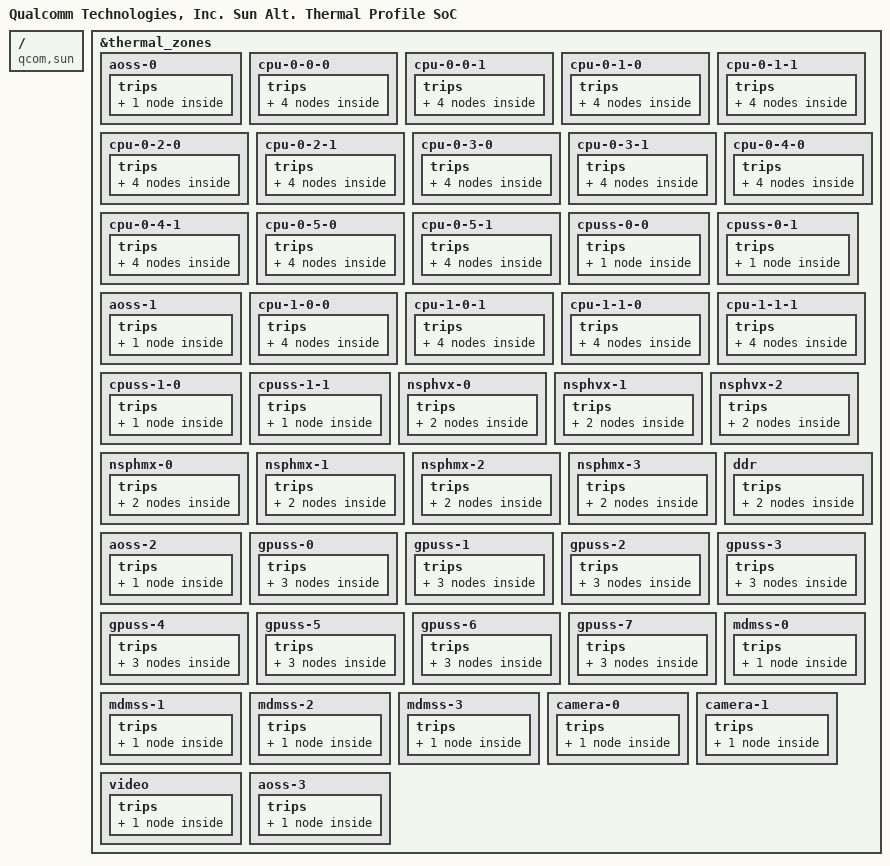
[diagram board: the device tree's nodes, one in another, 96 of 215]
// SPDX-License-Identifier: BSD-3-Clause
/*
 * Copyright (c) 2024 Qualcomm Innovation Center, Inc. All rights reserved.
 */

/ {
	model = "Qualcomm Technologies, Inc. Sun Alt. Thermal Profile SoC";
	compatible = "qcom,sun";
	qcom,msm-id = <0x100026a 0x10000>;
};

&thermal_zones {
	aoss-0 {
		trips {
			reset-mon-cfg {
				temperature = <125000>;
			};
		};
	};

	cpu-0-0-0 {
		trips {
			thermal-hal-config {
				temperature = <105000>;
			};

			cpu0-emerg0-cfg {
				temperature = <95000>;
			};

			cpu0-emerg0-1-cfg {
				temperature = <120000>;
			};

			reset-mon-cfg {
				temperature = <125000>;
			};
		};
	};

	cpu-0-0-1 {
		trips {
			thermal-hal-config {
				temperature = <105000>;
			};

			cpu0-emerg1-cfg {
				temperature = <118000>;
			};

			cpu0-emerg1-1-cfg {
				temperature = <120000>;
			};

			reset-mon-cfg {
				temperature = <125000>;
			};
		};
	};

	cpu-0-1-0 {
		trips {
			thermal-hal-config {
				temperature = <105000>;
			};

			cpu1-emerg0-cfg {
				temperature = <118000>;
			};

			cpu1-emerg0-1-cfg {
				temperature = <120000>;
			};

			reset-mon-cfg {
				temperature = <125000>;
			};
		};
	};

	cpu-0-1-1 {
		trips {
			thermal-hal-config {
				temperature = <105000>;
			};

			cpu1-emerg1-cfg {
				temperature = <118000>;
			};

			cpu1-emerg1-1-cfg {
				temperature = <120000>;
			};

			reset-mon-cfg {
				temperature = <125000>;
			};
		};
	};

	cpu-0-2-0 {
		trips {
			thermal-hal-config {
				temperature = <105000>;
			};

			cpu2-emerg0-cfg {
				temperature = <95000>;
			};

			cpu2-emerg0-1-cfg {
				temperature = <120000>;
			};

			reset-mon-cfg {
				temperature = <125000>;
			};
		};
	};

	cpu-0-2-1 {
		trips {
			thermal-hal-config {
				temperature = <105000>;
			};

			cpu2-emerg1-cfg {
				temperature = <95000>;
			};

			cpu2-emerg1-1-cfg {
				temperature = <120000>;
			};

			reset-mon-cfg {
				temperature = <125000>;
			};
		};
	};

	cpu-0-3-0 {
		trips {
			thermal-hal-config {
				temperature = <105000>;
			};

			cpu3-emerg0-cfg {
				temperature = <118000>;
			};

			cpu3-emerg0-1-cfg {
				temperature = <120000>;
			};

			reset-mon-cfg {
				temperature = <125000>;
			};
		};
	};

	cpu-0-3-1 {
		trips {
			thermal-hal-config {
				temperature = <105000>;
			};

			cpu3-emerg1-cfg {
				temperature = <118000>;
			};

			cpu3-emerg1-1-cfg {
				temperature = <120000>;
			};

			reset-mon-cfg {
				temperature = <125000>;
			};
		};
	};

	cpu-0-4-0 {
		trips {
			thermal-hal-config {
				temperature = <105000>;
			};

			cpu4-emerg0-cfg {
				temperature = <95000>;
			};

			cpu4-emerg0-1-cfg {
				temperature = <120000>;
			};

			reset-mon-cfg {
				temperature = <125000>;
			};
		};
	};

	cpu-0-4-1 {
		trips {
			thermal-hal-config {
				temperature = <105000>;
			};

			cpu4-emerg1-cfg {
				temperature = <95000>;
			};

			cpu4-emerg1-1-cfg {
				temperature = <120000>;
			};

			reset-mon-cfg {
				temperature = <125000>;
			};
		};
	};

	cpu-0-5-0 {
		trips {
			thermal-hal-config {
				temperature = <105000>;
			};

			cpu5-emerg0-cfg {
				temperature = <118000>;
			};

			cpu5-emerg0-1-cfg {
				temperature = <120000>;
			};

			reset-mon-cfg {
				temperature = <125000>;
			};
		};
	};

	cpu-0-5-1 {
		trips {
			thermal-hal-config {
				temperature = <105000>;
			};

			cpu5-emerg1-cfg {
				temperature = <118000>;
			};

			cpu5-emerg1-1-cfg {
				temperature = <120000>;
			};

			reset-mon-cfg {
				temperature = <125000>;
			};
		};
	};

	cpuss-0-0 {
		trips {
			reset-mon-cfg {
				temperature = <125000>;
			};
		};
	};

	cpuss-0-1 {
		trips {
			reset-mon-cfg {
				temperature = <125000>;
			};
		};
	};

	aoss-1 {
		trips {
			reset-mon-cfg {
				temperature = <125000>;
			};
		};
	};

	cpu-1-0-0 {
		trips {
			thermal-hal-config {
				temperature = <105000>;
			};

			cpu6-emerg0-cfg {
				temperature = <95000>;
			};

			cpu6-emerg0-1-cfg {
				temperature = <120000>;
			};

			reset-mon-cfg {
				temperature = <125000>;
			};
		};
	};

	cpu-1-0-1 {
		trips {
			thermal-hal-config {
				temperature = <105000>;
			};

			cpu6-emerg1-cfg {
				temperature = <95000>;
			};

			cpu6-emerg1-1-cfg {
				temperature = <120000>;
			};

			reset-mon-cfg {
				temperature = <125000>;
			};
		};
	};

	cpu-1-1-0 {
		trips {
			thermal-hal-config {
				temperature = <105000>;
			};

			cpu7-emerg0-cfg {
				temperature = <95000>;
			};

			cpu7-emerg0-1-cfg {
				temperature = <120000>;
			};

			reset-mon-cfg {
				temperature = <125000>;
			};
		};
	};

	cpu-1-1-1 {
		trips {
			thermal-hal-config {
				temperature = <105000>;
			};

			cpu7-emerg1-cfg {
				temperature = <95000>;
			};

			cpu7-emerg1-1-cfg {
				temperature = <120000>;
			};

			reset-mon-cfg {
				temperature = <125000>;
			};
		};
	};

	cpuss-1-0 {
		trips {
			reset-mon-cfg {
				temperature = <125000>;
			};
		};
	};

	cpuss-1-1 {
		trips {
			reset-mon-cfg {
				temperature = <125000>;
			};
		};
	};

	nsphvx-0 {
		trips {
			thermal-hal-config {
				temperature = <105000>;
			};

			reset-mon-cfg {
				temperature = <125000>;
			};
		};
	};

	nsphvx-1 {
		trips {
			thermal-hal-config {
				temperature = <105000>;
			};

			reset-mon-cfg {
				temperature = <125000>;
			};
		};
	};

	nsphvx-2 {
		trips {
			thermal-hal-config {
				temperature = <105000>;
			};

			reset-mon-cfg {
				temperature = <125000>;
			};
		};
	};

	nsphmx-0 {
		trips {
			thermal-hal-config {
				temperature = <105000>;
			};

			reset-mon-cfg {
				temperature = <125000>;
			};
		};
	};

	nsphmx-1 {
		trips {
			thermal-hal-config {
				temperature = <105000>;
			};

			reset-mon-cfg {
				temperature = <125000>;
			};
		};
	};

	nsphmx-2 {
		trips {
			thermal-hal-config {
				temperature = <105000>;
			};

			reset-mon-cfg {
				temperature = <125000>;
			};
		};
	};

	nsphmx-3 {
		trips {
			thermal-hal-config {
				temperature = <105000>;
			};

			reset-mon-cfg {
				temperature = <125000>;
			};
		};
	};

	ddr {
		trips {
			ddr0-config {
				temperature = <100000>;
			};

			reset-mon-cfg {
				temperature = <125000>;
			};
		};
	};

	aoss-2 {
		trips {
			reset-mon-cfg {
				temperature = <125000>;
			};
		};
	};

	gpuss-0 {
		trips {
			thermal-hal-config {
				temperature = <105000>;
			};

			tj_cfg {
                temperature = <95000>;
			};

			reset-mon-cfg {
				temperature = <125000>;
			};
		};
	};

	gpuss-1 {
		trips {
			thermal-hal-config {
				temperature = <105000>;
			};

			tj_cfg {
                temperature = <95000>;
			};

			reset-mon-cfg {
				temperature = <125000>;
			};
		};
	};

	gpuss-2 {
		trips {
			thermal-hal-config {
				temperature = <105000>;
			};

			tj_cfg {
                temperature = <95000>;
			};

			reset-mon-cfg {
				temperature = <125000>;
			};
		};
	};

	gpuss-3 {
		trips {
			thermal-hal-config {
				temperature = <105000>;
			};

			tj_cfg {
                temperature = <95000>;
			};

			reset-mon-cfg {
				temperature = <125000>;
			};
		};
	};

	gpuss-4 {
		trips {
			thermal-hal-config {
				temperature = <105000>;
			};

			tj_cfg {
                temperature = <95000>;
			};

			reset-mon-cfg {
				temperature = <125000>;
			};
		};
	};

	gpuss-5 {
		trips {
			thermal-hal-config {
				temperature = <105000>;
			};

			tj_cfg {
                temperature = <95000>;
			};

			reset-mon-cfg {
				temperature = <125000>;
			};
		};
	};

	gpuss-6 {
		trips {
			thermal-hal-config {
				temperature = <105000>;
			};

			tj_cfg {
                temperature = <95000>;
			};

			reset-mon-cfg {
				temperature = <125000>;
			};
		};
	};

	gpuss-7 {
		trips {
			thermal-hal-config {
				temperature = <105000>;
			};

			tj_cfg {
                temperature = <95000>;
			};

			reset-mon-cfg {
				temperature = <125000>;
			};
		};
	};

	mdmss-0 {
		trips {
			reset-mon-cfg {
				temperature = <125000>;
			};
		};
	};

	mdmss-1 {
		trips {
			reset-mon-cfg {
				temperature = <125000>;
			};
		};
	};

	mdmss-2 {
		trips {
			reset-mon-cfg {
				temperature = <125000>;
			};
		};
	};

	mdmss-3 {
		trips {
			reset-mon-cfg {
				temperature = <125000>;
			};
		};
	};

	camera-0 {
		trips {
			reset-mon-cfg {
				temperature = <125000>;
			};
		};
	};

	camera-1 {
		trips {
			reset-mon-cfg {
				temperature = <125000>;
			};
		};
	};

	video {
		trips {
			reset-mon-cfg {
				temperature = <125000>;
			};
		};
	};

	aoss-3 {
		trips {
			reset-mon-cfg {
				temperature = <125000>;
			};
		};
	};
};
